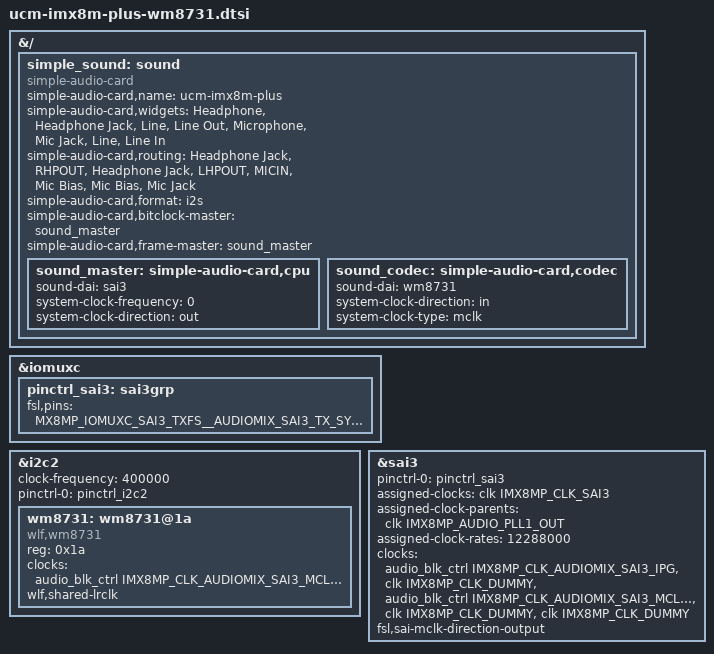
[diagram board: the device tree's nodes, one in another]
/*
 * Copyright 2024 CompuLab
 *
 * This program is free software; you can redistribute it and/or
 * modify it under the terms of the GNU General Public License
 * as published by the Free Software Foundation; either version 2
 * of the License, or (at your option) any later version.
 *
 * This program is distributed in the hope that it will be useful,
 * but WITHOUT ANY WARRANTY; without even the implied warranty of
 * MERCHANTABILITY or FITNESS FOR A PARTICULAR PURPOSE.  See the
 * GNU General Public License for more details.
 */

&{/} {
	simple_sound: sound {
		compatible = "simple-audio-card";
		simple-audio-card,name = "ucm-imx8m-plus";
		simple-audio-card,widgets =
			"Headphone", "Headphone Jack",
			"Line", "Line Out",
			"Microphone", "Mic Jack",
			"Line", "Line In";
		simple-audio-card,routing =
			"Headphone Jack", "RHPOUT",
			"Headphone Jack", "LHPOUT",
			"MICIN", "Mic Bias",
			"Mic Bias", "Mic Jack";
		simple-audio-card,format = "i2s";
		simple-audio-card,bitclock-master = <&sound_master>;
		simple-audio-card,frame-master = <&sound_master>;

		sound_master: simple-audio-card,cpu {
			sound-dai = <&sai3>;
			system-clock-frequency = <0>;
			system-clock-direction = "out";
		};

		sound_codec: simple-audio-card,codec {
			sound-dai = <&wm8731>;
			system-clock-direction = "in";
			system-clock-type = "mclk";
		};
	};
};

&iomuxc {
	pinctrl_sai3: sai3grp {
		fsl,pins = <
			MX8MP_IOMUXC_SAI3_TXFS__AUDIOMIX_SAI3_TX_SYNC	0xd6
			MX8MP_IOMUXC_SAI3_TXC__AUDIOMIX_SAI3_TX_BCLK	0xd6
			MX8MP_IOMUXC_SAI3_RXD__AUDIOMIX_SAI3_RX_DATA00	0xd6
			MX8MP_IOMUXC_SAI3_TXD__AUDIOMIX_SAI3_TX_DATA00	0xd6
			MX8MP_IOMUXC_SAI3_MCLK__AUDIOMIX_SAI3_MCLK	0xd6
			MX8MP_IOMUXC_SAI3_RXFS__GPIO4_IO28		0xd6
			MX8MP_IOMUXC_SAI3_RXC__GPIO4_IO29		0xd6
		>;
	};
};

&i2c2 {
	clock-frequency = <400000>;
	pinctrl-names = "default";
	pinctrl-0 = <&pinctrl_i2c2>;
	#address-cells = <1>;
	#size-cells = <0>;
	status = "okay";

	wm8731: wm8731@1a {
		#sound-dai-cells = <0>;
		compatible = "wlf,wm8731";
		reg = <0x1a>;
		clocks = <&audio_blk_ctrl IMX8MP_CLK_AUDIOMIX_SAI3_MCLK1>;
		clock-names = "mclk";
		wlf,shared-lrclk;
    		status = "okay";
	};
};

&sai3 {
	#sound-dai-cells = <0>;
	pinctrl-names = "default";
	pinctrl-0 = <&pinctrl_sai3>;
	assigned-clocks = <&clk IMX8MP_CLK_SAI3>;
	assigned-clock-parents = <&clk IMX8MP_AUDIO_PLL1_OUT>;
	assigned-clock-rates = <12288000>;
	clocks = <&audio_blk_ctrl IMX8MP_CLK_AUDIOMIX_SAI3_IPG>, <&clk IMX8MP_CLK_DUMMY>,
		 <&audio_blk_ctrl IMX8MP_CLK_AUDIOMIX_SAI3_MCLK1>, <&clk IMX8MP_CLK_DUMMY>,
		 <&clk IMX8MP_CLK_DUMMY>;
	clock-names = "bus", "mclk0", "mclk1", "mclk2", "mclk3";
	fsl,sai-mclk-direction-output;
	status = "okay";
};
